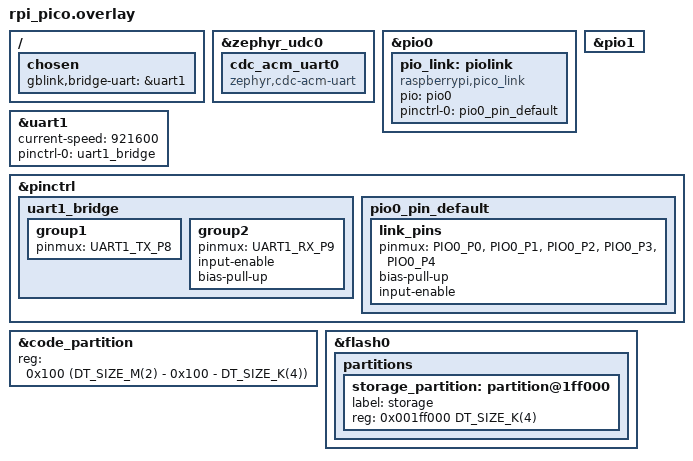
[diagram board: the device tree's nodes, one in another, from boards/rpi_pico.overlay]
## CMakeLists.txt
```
cmake_minimum_required(VERSION 3.20.0)

set(CMAKE_CXX_STANDARD 20)
set(CMAKE_CXX_STANDARD_REQUIRED ON)

# The following resolves the Zephyr location using the ZEPHYR_BASE environment variable.
# The `REQUIRED HINTS $ENV{ZEPHYR_BASE}` is optional in case you're not using `west zephyr-export`
# https://docs.zephyrproject.org/latest/develop/west/zephyr-cmds.html#installing-cmake-packages-west-zephyr-export

# Only set ZEPHYR_MODULES manually if modules are vendored locally.
# When building with west, modules are discovered automatically.
if(EXISTS "${CMAKE_SOURCE_DIR}/modules/hal/rpi_pico")
    set(ZEPHYR_MODULES "${CMAKE_SOURCE_DIR}/modules/hal/rpi_pico" "${CMAKE_SOURCE_DIR}/modules/hal/cmsis")
endif()

set(BOARD rpi_pico)

find_package(Zephyr REQUIRED HINTS "${CMAKE_SOURCE_DIR}/zephyr" $ENV{ZEPHYR_BASE})

project(
    EmptyApp
    VERSION 0.1
    DESCRIPTION "Empty Zephyr application."
    LANGUAGES C
)

# The target "app" is defined in Zephyr's CMake package and is the default target for Zephyr apps.
target_sources(
    app
    PRIVATE
    src/main.cpp
    src/hardware.cpp
    src/persist.cpp
)

set_compiler_property(PROPERTY diagnostic -fdiagnostics-color=never)


# The wireless adapter's transfer path runs from RAM: the GBA clocks the next
# word about 40us after the last, and executing ~4KB of protocol code in place
# shares the RP2040's 16KB XIP cache with the kernel, bridge UART and USB, where
# a cold pass costs more than that whole budget.
zephyr_code_relocate(FILES src/layers/link/rfuLinkLayer.c src/sections/rfuProtocolSection.cpp
                     LOCATION RAM_TEXT)

add_subdirectory(src/layers)
add_subdirectory(src/sections)
add_subdirectory(src/module)
```

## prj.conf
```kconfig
CONFIG_GPIO=y
CONFIG_DMA=y
CONFIG_COUNTER=y
CONFIG_EVENTS=y

CONFIG_SPEED_OPTIMIZATIONS=y
CONFIG_DEBUG=n

CONFIG_STDOUT_CONSOLE=y
CONFIG_USB_DEVICE_STACK=y
CONFIG_USB_DEVICE_BOS=y
CONFIG_USB_COMPOSITE_DEVICE=y
CONFIG_USB_CDC_ACM=y
# Composite (vendor + CDC) needs more concurrent transfers than the defaults.
CONFIG_USB_MAX_NUM_TRANSFERS=8
CONFIG_USB_NUMOF_EP_WRITE_RETRIES=10
CONFIG_SERIAL=y
CONFIG_USB_DEVICE_PRODUCT="GBLink USB"
CONFIG_USB_DEVICE_VID=0x1209
CONFIG_USB_DEVICE_PID=0xB011
CONFIG_UART_INTERRUPT_DRIVEN=y
CONFIG_UART_LINE_CTRL=y
CONFIG_RING_BUFFER=y
CONFIG_USB_DEVICE_INITIALIZE_AT_BOOT=n

CONFIG_CPP=y
CONFIG_STD_CPP20=y
CONFIG_NEWLIB_LIBC=y
CONFIG_NEWLIB_LIBC_NANO=y
CONFIG_REQUIRES_FULL_LIBCPP=y

CONFIG_TICKLESS_KERNEL=y

CONFIG_THREAD_MONITOR=y
CONFIG_THREAD_NAME=y
CONFIG_DEBUG_THREAD_INFO=y
CONFIG_ASSERT=y

CONFIG_PINCTRL=y

# Flash storage for persistent settings (the WebUSB landing-page toggle).
CONFIG_FLASH=y
CONFIG_FLASH_MAP=y
CONFIG_FLASH_PAGE_LAYOUT=y

CONFIG_SECTIONS_USE_MASTER_MODE=y
CONFIG_REBOOT=y
# Driving SD low is opt-in (off by default). For rare compatibility issues with some GBAs.
CONFIG_GB_LINK_DRIVE_SD_LOW=n

# Lets zephyr_code_relocate() place the wireless adapter's transfer path in RAM.
CONFIG_CODE_DATA_RELOCATION=y
```

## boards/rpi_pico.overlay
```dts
#include <zephyr/dt-bindings/pinctrl/rpi-pico-rp2040-pinctrl.h>

&zephyr_udc0 {
    cdc_acm_uart0: cdc_acm_uart0 {
        compatible = "zephyr,cdc-acm-uart";
    };
};

&pio0 {
    status = "okay";

    pio_link: piolink {
        compatible = "raspberrypi,pico_link";
        status = "okay";
        pio = <&pio0>;
        pinctrl-0 = <&pio0_pin_default>;
        pinctrl-names = "default";
    };
};

&pio1 {
    status = "okay";
};

/*
 * Bridge UART: the same 'GB' framed transport CDC-ACM carries, but wired
 * directly to a companion MCU instead of a host PC. GP8/GP9 is the only
 */
&uart1 {
    status = "okay";
    current-speed = <921600>;
    pinctrl-0 = <&uart1_bridge>;
    pinctrl-names = "default";
};

/ {
    chosen {
        gblink,bridge-uart = &uart1;
    };
};

&pinctrl {
    uart1_bridge: uart1_bridge {
        group1 {
            pinmux = <UART1_TX_P8>;
        };
        group2 {
            pinmux = <UART1_RX_P9>;
            input-enable;
            bias-pull-up;
        };
    };
    pio0_pin_default: pio0_pin_default {
        link_pins {
            pinmux = <PIO0_P0>, <PIO0_P1>, <PIO0_P2>, <PIO0_P3>, <PIO0_P4>;
            bias-pull-up;
            input-enable;
        };
    };
};

/*
 * Carve a 4 KB storage partition (one flash erase sector) off the top of flash
 * for persistent settings (URL toggle and LED customization). The application is
 * less than 200 KB and lives at the bottom, so the tail is free. The UF2 only writes
 * the app region, so this sector survives firmware updates.
 */
&code_partition {
    reg = <0x100 (DT_SIZE_M(2) - 0x100 - DT_SIZE_K(4))>;
};

&flash0 {
    partitions {
        storage_partition: partition@1ff000 {
            label = "storage";
            reg = <0x001ff000 DT_SIZE_K(4)>;
        };
    };
};
```

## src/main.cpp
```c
#include <zephyr/kernel.h>

#include "control.hpp"

#include "link_defines.h"

int main(void)
{
    Control g_control = Control();
    while (true)
    {
        g_control.executeMode();
    }

    return 0;
}
```

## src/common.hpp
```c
#include <algorithm>
#include <array>
#include <concepts>
#include <cstdint>
#include <span>
#include <stdint.h>

#pragma once

class TxValues
{
public:

    TxValues() = default;

    template<std::convertible_to<uint16_t>... Ts>
        requires (sizeof...(Ts) <= 3)
    TxValues(Ts... values)
        : m_count(sizeof...(Ts)), m_values{static_cast<uint16_t>(values)...}
    {}

    uint8_t size() { return m_count; }

    void push(uint16_t value) 
    { 
        m_values[m_count] = value;
        m_count++;    
    }

    const uint16_t& operator[](size_t index) {return m_values[index]; }

    std::span<const uint16_t> span() { return std::span(m_values).first(m_count); }

    auto begin() { return m_values.begin(); }

    auto end() { return m_values.begin() + m_count; }

    auto begin() const { return m_values.cbegin(); }

    auto end() const { return m_values.cbegin() + m_count; } 

private:

    uint8_t m_count = 0;
    std::array<uint16_t, 3> m_values = {};
};
```

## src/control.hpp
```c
#include "layers/transport.hpp"
#include "layers/packet/packetLayer.hpp"
#include "module/link.hpp"
#include "module/gb.hpp"
#include "module/advanceWars.hpp"
#include "module/eReader.hpp"
#include "module/battleChipGate.hpp"
#include "module/rfuWireless.hpp"
#include "sections/eReaderProtocolSection.hpp"
#include "sections/battleChipGateSection.hpp"
#include "sections/rfuProtocolSection.hpp"
#include "linkStatus.hpp"
#include "layers/packet/packetCommands/commands.hpp"
#include "module/moduleInterface.hpp"
#include "hardware.hpp"
#include "persist.hpp"
#include "firmware_version.hpp"

class Control
{
    enum class ControlCommand
    {
        SetMode = 0x00,
        Cancel = 0x01,
        EnterGBPrinter = 0x03,
        GetFirmwareInfo = 0x0F
    };

    enum class Mode
    {
        gbaLink = 0x01,
        gbLink = 0x02,
        gbPrinter = 0x03,
        advanceWars = 0x04,
        gbaEreader = 0x05,
        battleChipGate = 0x06,
        rfuWireless = 0x07,
    };

    static constexpr uint8_t callSetModeId = 0x01;

public:
    Control()
    {
        Transport::registerCommandHandler(receiveCommandHandler, this);

        k_sem_init(&m_waitForModeSemaphore, 0, 1);
    }

    void executeMode()
    {
        k_sem_take(&m_waitForModeSemaphore, K_FOREVER);
        // Capture the requested mode; callSetMode always sets m_mode before
        // giving the semaphore (including when preempting a running mode), so we
        // must not clobber it below. The variant travels with the mode.
        const Mode mode = m_mode;
        const uint8_t modeVariant = m_modeVariant;
        if (mode != m_previousMode) link_forgetSdPin();
        m_previousMode = mode;

        sendLinkStatus(LinkStatus::DeviceReady);

        switch (mode)
        {
            case Mode::gbaLink:
            {
                applyLedForSlot(LED_SLOT_GBA);

                Transport::registerDataHandler(usbLink_receiveHandler, nullptr);

                LinkModule linkModule;
                m_currentModule = &linkModule;
                linkModule.execute();

                sendLinkStatus(LinkStatus::LinkClosed);
                break;
            }

            case Mode::gbLink:
            {
                GBModule gbModule;
                m_currentModule = &gbModule;
                gbModule.execute();  // Sets blue LED internally

                sendLinkStatus(LinkStatus::GBSessionFinished);
                break;
            }

            case Mode::gbPrinter:
            {
                GBModule gbModule;
                m_currentModule = &gbModule;
                gbModule.executePrinterMode();  // Sets purple LED internally

                sendLinkStatus(LinkStatus::GBSessionFinished);
                break;
            }

            case Mode::advanceWars:
            {
                applyLedForSlot(LED_SLOT_ADVANCE_WARS);

                Transport::registerDataHandler(awProto_receiveHandler, nullptr);

                AdvanceWarsModule advanceWarsModule(
                    modeVariant == 2 ? awproto::GameVariant::aw2
                                     : awproto::GameVariant::aw1);
                m_currentModule = &advanceWarsModule;
                advanceWarsModule.execute();

                sendLinkStatus(LinkStatus::LinkClosed);
                break;
            }

            case Mode::gbaEreader:
            {
                applyLedForSlot(LED_SLOT_EREADER);

                Transport::registerDataHandler(erProto_receiveHandler, nullptr);

                const erproto::Profile profile =
                    modeVariant == 2 ? erproto::Profile::pokemonRuby :
                    modeVariant == 3 ? erproto::Profile::sma4JPN :
                    modeVariant == 4 ? erproto::Profile::pokemonRubyJPN :
                    modeVariant == 5 ? erproto::Profile::sma4EUR :
                    modeVariant == 6 ? erproto::Profile::sma4EURFra :
                    modeVariant == 7 ? erproto::Profile::sma4EURGer :
                    modeVariant == 8 ? erproto::Profile::sma4EUREsp :
                    modeVariant == 9 ? erproto::Profile::sma4EURIta :
                    modeVariant == 10 ? erproto::Profile::pokemonEmerald :
                    modeVariant == 11 ? erproto::Profile::pokemonEmeraldJPN :
                    modeVariant == 12 ? erproto::Profile::pokemonEmeraldFra :
                    modeVariant == 13 ? erproto::Profile::pokemonEmeraldGer
                                   : erproto::Profile::sma4;
                EReaderModule ereaderModule(profile);
                m_currentModule = &ereaderModule;
                ereaderModule.execute();

                sendLinkStatus(LinkStatus::LinkClosed);
                break;
            }

            case Mode::battleChipGate:
            {
                applyLedForSlot(LED_SLOT_BATTLE_CHIP_GATE);

                Transport::registerDataHandler(bcgProto_receiveHandler, nullptr);

                BattleChipGateModule battleChipGateModule(
                    bcgproto::gateTypeFromVariant(modeVariant));
                m_currentModule = &battleChipGateModule;
                battleChipGateModule.execute();

                sendLinkStatus(LinkStatus::LinkClosed);
                break;
            }

            // Wireless adapter (AGB-015) emulation, driven over the bridge UART
            // by a companion MCU rather than a host PC.
            case Mode::rfuWireless:
            {
                // No slot of its own: the stored palette holds seven entries and
                // an eighth would change the settings layout.
                applyLedForSlot(LED_SLOT_GBA);

                Transport::registerDataHandler(rfuProto_receiveHandler, nullptr);

                // Variant = role hint for the relay: 0 symmetric, 1 host, 2 client.
                RfuWirelessModule rfuModule(modeVariant);
                m_currentModule = &rfuModule;
                rfuModule.execute();

                sendLinkStatus(LinkStatus::LinkClosed);
                break;
            }
        }

        m_currentModule = nullptr;
        applyLedForSlot(LED_SLOT_IDLE); // green = connected, no active mode
    }

private:
    struct k_sem m_waitForModeSemaphore;
    Mode m_mode;
    uint8_t m_modeVariant = 0;
    std::optional<Mode> m_previousMode;

    IModule* m_currentModule = nullptr;

    bool canHandle(uint8_t command) { return (command & 0xF0) == 0x00; }

    // Hardware commands (0x40-0x4F) are device-level, handled regardless of active module
    bool isHardwareCommand(uint8_t command) { return (command & 0xF0) == 0x40; }

    enum class HardwareCommand : uint8_t
    {
        SetVoltage3V3 = 0x40,
        SetVoltage5V = 0x41,
        SetLEDColor = 0x42,
        RebootBootloader = 0x43,
        SetWebUsbLanding = 0x44,
        GetLedConfig = 0x45,
        SetModeLedColor = 0x46,
        ResetLedColors = 0x47,
        Reboot = 0x48,
        GetRfuIsrStats = 0x4c,
    };

    void receiveCommand(std::span<const uint8_t> data)
    {
        if (data.empty()) return;

        // Handle hardware commands first (device-level, always available)
        if (isHardwareCommand(data[0]))
        {
            return handleHardwareCommand(data);
        }

        if (m_currentModule != nullptr && m_currentModule->canHandle(data[0]))
        {
            return m_currentModule->receiveCommand(data);
        } 
        
        if (!canHandle(data[0])) return;
        switch (static_cast<ControlCommand>(data[0]))
        {
            // Optional third byte selects a game variant within the mode
            // (Advance Wars: 1 = AW1, 2 = AW2; e-reader: 1 = SMA4 US,
            // 2 = Pokemon RS US, 3 = SMA4 JPN, 4 = Pokemon RS JPN,
            // 5-9 = SMA4 EUR En/Fr/De/Es/It, 10 = Pokemon Emerald US,
            // 11 = Pokemon Emerald JPN, 12 = (Émeraude) / Emerald,
            // 13 = (Smaragd) / Emerald;
            // defaults to the first variant
            // for older clients that send only [command, mode]).
            case ControlCommand::SetMode:
                if (data.size() < 2) return;
                return callSetMode(static_cast<Mode>(data[1]),
                                   data.size() >= 3 ? data[2] : 0);
            case ControlCommand::Cancel: return callCancel();
            case ControlCommand::EnterGBPrinter: return callSetMode(Mode::gbPrinter);
            case ControlCommand::GetFirmwareInfo: return callGetFirmwareInfo();
            default: return;
        }
    }

    void handleHardwareCommand(std::span<const uint8_t> data)
    {
        switch (static_cast<HardwareCommand>(data[0]))
        {
            case HardwareCommand::SetVoltage3V3:
                Hardware::getInstance().setVoltage3V3();
                break;
            case HardwareCommand::SetVoltage5V:
                Hardware::getInstance().setVoltage5V();
                break;
            case HardwareCommand::SetLEDColor:
                if (data.size() >= 5) {
                    Hardware::getInstance().setLED(data[1], data[2], data[3], data[4] != 0);
                }
                break;
            case HardwareCommand::RebootBootloader:
                // Resets into the USB bootloader; does not return.
                Hardware::getInstance().rebootToBootloader();
                break;
            case HardwareCommand::SetWebUsbLanding:
                // Persist the WebUSB landing-page toggle; applies on next reconnect.
                if (data.size() >= 2) {
                    setLandingPageEnabled(data[1] != 0);
                }
                break;
            case HardwareCommand::GetLedConfig:
                return callGetLedConfig();
            case HardwareCommand::SetModeLedColor:
                // [0x46, slot, r, g, b] — persist a mode's LED colour.
                if (data.size() >= 5) {
                    setLedColor(data[1], data[2], data[3], data[4]);
                }
                break;
            case HardwareCommand::ResetLedColors:
                // Restore all per-mode LED colours to the built-in defaults.
                resetLedColors();
                break;
            case HardwareCommand::Reboot:
                // Warm-reboot into the app so persisted settings apply now; no return.
                Hardware::getInstance().reboot(); 
                break;
            case HardwareCommand::GetRfuIsrStats:
            {
                // Transfer-path timing: whether replies are staged inside the
                // GBA's inter-word gap.
                uint32_t v[5];
                rfuLink_isrStats(v);
                uint8_t resp[1 + sizeof(v)];
                resp[0] = 0x4c;
                for (unsigned i = 0; i < 5; i++)
                    for (unsigned b = 0; b < 4; b++)
                        resp[1 + i * 4 + b] = static_cast<uint8_t>(v[i] >> (8 * b));
                Transport::sendData(std::span<const uint8_t>(resp, sizeof(resp)));
                break;
            }
            default: break;
        }
    }

    void callGetLedConfig()
    {
        // [0x45, count, r0,g0,b0, ... r5,g5,b5]
        uint8_t info[2 + LED_SLOT_COUNT * 3];
        info[0] = static_cast<uint8_t>(HardwareCommand::GetLedConfig);
        info[1] = LED_SLOT_COUNT;
        for (uint8_t slot = 0; slot < LED_SLOT_COUNT; slot++) {
            getLedColor(slot, &info[2 + slot * 3]);
        }
        Transport::sendData(std::span<const uint8_t>(info, sizeof(info)));
    }

    //-////////////////////////////////////////////////////////////////////////////////////////////////////////-//
    // CALLS
    //-////////////////////////////////////////////////////////////////////////////////////////////////////////-//

    void callSetMode(Mode mode, uint8_t variant = 0)
    {
        m_mode = mode;
        m_modeVariant = variant;
        // If a mode is already running, cancel it so executeMode unblocks and
        // switches to the new mode (otherwise SetMode would queue behind a mode
        // that never exits). Same cancel path the web "cancel" command uses.
        if (m_currentModule != nullptr)
        {
            m_currentModule->cancel();
        }
        k_sem_give(&m_waitForModeSemaphore);
    }

    void callCancel()
    {
        if (m_currentModule != nullptr) m_currentModule->cancel();
    }

    void callGetFirmwareInfo()
    {
        const uint8_t info[] = {
            0x0F, // Echo back the command ID so web app knows this is a firmware info response
            fw::versionMajor,
            fw::versionMinor,
            fw::versionPatch,
            // Byte 4: WebUSB landing-page enabled (1) / disabled (0). Older web
            // apps simply ignore the extra byte.
            static_cast<uint8_t>(landingPageEnabled() ? 1 : 0)
        };
        Transport::sendData(std::span<const uint8_t>(info, sizeof(info)));
    }

    //-////////////////////////////////////////////////////////////////////////////////////////////////////////-//

    static void receiveCommandHandler(std::span<const uint8_t> receivedData, void* userData)
    {
        Control* self = static_cast<Control*>(userData);
        self->receiveCommand(receivedData);
    }
};
```

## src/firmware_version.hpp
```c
#pragma once

#include <cstdint>

// Single source for the firmware version. It is reported over the
// protocol (GetFirmwareInfo) and folded into the USB bcdDevice (see usbLayer.cpp).
//
// Why bcdDevice tracks the version: Windows caches a device's MS OS / WinUSB
// driver binding keyed by VID/PID/bcdDevice. If bcdDevice never changes, a host
// that cached an older descriptor keeps the stale binding after a firmware
// update and will not re-read the corrected descriptors. Advancing bcdDevice on
// every release makes Windows treat it as a new device and re-enumerate cleanly.
namespace fw
{
    inline constexpr uint8_t versionMajor = 3;
    inline constexpr uint8_t versionMinor = 0;
    inline constexpr uint8_t versionPatch = 0;

    // Packed BCD nibbles 0x0<major><minor><patch>, e.g. 2.2.1 -> 0x0221.
    // Keep each field <= 9 to stay valid BCD.
    inline constexpr uint16_t bcdDevice =
        (static_cast<uint16_t>(versionMajor) << 8) |
        (static_cast<uint16_t>(versionMinor) << 4) |
        static_cast<uint16_t>(versionPatch);
}
```

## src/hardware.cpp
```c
#include "hardware.hpp"

#include <zephyr/kernel.h>
#include <zephyr/sys/reboot.h>
#include "hardware/pio.h"
#include "hardware/gpio.h"
#include "hardware/clocks.h"
#include "hardware/timer.h"

extern "C" {
#include <zephyr/drivers/misc/pio_rpi_pico/pio_rpi_pico.h>
}

// --- Pin Definitions ---
#define WS2812_PIN      16
#define VSWITCH_3V3_PIN 11
#define VSWITCH_5V_PIN  12

// --- WS2812 PIO Program (4 instructions) ---
static const uint16_t ws2812_program_instructions[] = {
    0x6221, //  0: out    x, 1       side 0 [2]
    0x1123, //  1: jmp    !x, 3      side 1 [1]
    0x1400, //  2: jmp    0          side 1 [4]
    0xa442, //  3: nop               side 0 [4]
};

static const struct pio_program ws2812_program = {
    .instructions = ws2812_program_instructions,
    .length = 4,
    .origin = -1,
};

// WS2812 uses pio1 (independent from link SPI on pio0)
static PIO g_ws2812_pio = NULL;
static uint g_ws2812_sm = 0;
static bool g_ws2812_initialized = false;

// --- Hardware Singleton ---

Hardware& Hardware::getInstance()
{
    static Hardware instance;
    return instance;
}

Hardware::Hardware()
{
    // Initialize voltage switching GPIOs (raw Pico SDK, matching linkLayer_pio.c pattern)
    gpio_init(VSWITCH_3V3_PIN);
    gpio_init(VSWITCH_5V_PIN);
    gpio_set_dir(VSWITCH_3V3_PIN, GPIO_OUT);
    gpio_set_dir(VSWITCH_5V_PIN, GPIO_OUT);

    // Safe state: both HIGH first
    gpio_put(VSWITCH_3V3_PIN, 1);
    gpio_put(VSWITCH_5V_PIN, 1);
    busy_wait_us(100);

    // Default to 3.3V mode
    gpio_put(VSWITCH_3V3_PIN, 0);

    // Initialize WS2812 NeoPixel
    ws2812Init();

    // Set initial LED to red (disconnected state)
    ws2812Set(0x000500); // GRB format: G=0x00, R=0x05, B=0x00
}

void Hardware::ws2812Init()
{
    // Pico SDK defines 'pio1' as a macro (pio1_hw) which breaks DT_NODELABEL.
    // Temporarily undefine it so device tree lookup works.
    #undef pio1
    const struct device* dev = DEVICE_DT_GET(DT_NODELABEL(pio1));
    if (!device_is_ready(dev)) {
        return;
    }

    g_ws2812_pio = pio_rpi_pico_get_pio(dev);
    pio_rpi_pico_allocate_sm(dev, &g_ws2812_sm);

    uint offset = pio_add_program(g_ws2812_pio, &ws2812_program);

    // Configure state machine for WS2812 protocol
    pio_gpio_init(g_ws2812_pio, WS2812_PIN);
    pio_sm_set_consecutive_pindirs(g_ws2812_pio, g_ws2812_sm, WS2812_PIN, 1, true);

    pio_sm_config c = pio_get_default_sm_config();
    sm_config_set_sideset(&c, 1, false, false);
    sm_config_set_sideset_pins(&c, WS2812_PIN);
    sm_config_set_out_shift(&c, false, true, 24);
    sm_config_set_fifo_join(&c, PIO_FIFO_JOIN_TX);
    sm_config_set_wrap(&c, offset, offset + 3);
    sm_config_set_clkdiv(&c, clock_get_hz(clk_sys) / (800000.0f * 8.0f));

    pio_sm_init(g_ws2812_pio, g_ws2812_sm, offset, &c);
    pio_sm_set_enabled(g_ws2812_pio, g_ws2812_sm, true);

    g_ws2812_initialized = true;
}

void Hardware::ws2812Set(uint32_t grb)
{
    if (!g_ws2812_initialized) return;
    pio_sm_put_blocking(g_ws2812_pio, g_ws2812_sm, grb << 8u);
}

// --- Public API ---

void Hardware::setVoltage3V3()
{
    // Both HIGH first (safe off), then pull 3.3V LOW
    gpio_put(VSWITCH_3V3_PIN, 1);
    gpio_put(VSWITCH_5V_PIN, 1);
    busy_wait_us(100);
    gpio_put(VSWITCH_3V3_PIN, 0);
}

void Hardware::setVoltage5V()
{
    // Both HIGH first (safe off), then pull 5V LOW
    gpio_put(VSWITCH_3V3_PIN, 1);
    gpio_put(VSWITCH_5V_PIN, 1);
    busy_wait_us(100);
    gpio_put(VSWITCH_5V_PIN, 0);
}

void Hardware::setLED(uint8_t r, uint8_t g, uint8_t b, bool on)
{
    if (on) {
        // NeoPixel expects GRB format
        uint32_t grb = ((uint32_t)g << 16) | ((uint32_t)r << 8) | b;
        ws2812Set(grb);
    } else {
        ws2812Set(0x000000);
    }
}

// Reset into the RP2040 USB bootloader (BOOTSEL/PICOBOOT) so the host can
// reflash over WebUSB. The Zephyr hal_rpi_pico module does not ship
// pico/bootrom.h, so look up reset_usb_boot() in the bootrom directly:
// the func-table pointer lives at 0x14 and the table-lookup routine at 0x18.
void Hardware::rebootToBootloader()
{
    typedef void *(*rom_table_lookup_fn)(uint16_t *table, uint32_t code);
    typedef void (*reset_usb_boot_fn)(uint32_t gpio_mask, uint32_t disable_mask);

    uint16_t *func_table = (uint16_t *)(uintptr_t)(*(uint16_t *)0x14);
    rom_table_lookup_fn rom_table_lookup =
        (rom_table_lookup_fn)(uintptr_t)(*(uint16_t *)0x18);

    const uint32_t reset_usb_boot_code = (uint32_t)('U' | ('B' << 8));
    reset_usb_boot_fn reset_usb_boot =
        (reset_usb_boot_fn)rom_table_lookup(func_table, reset_usb_boot_code);

    reset_usb_boot(0, 0); // does not return
}

// Warm-reboot back into the application (not the bootloader). Used to "apply now"
// after settings changes — persisted LED colours are re-read at boot.
void Hardware::reboot()
{
    sys_reboot(SYS_REBOOT_COLD); // does not return
}

// --- Boot-time Initialization ---
static int hardware_init()
{
    Hardware::getInstance();
    return 0;
}

SYS_INIT(hardware_init, APPLICATION, 0);
```

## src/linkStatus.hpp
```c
#include <zephyr/kernel.h>
#include "./layers/transport.hpp"

#pragma once

enum class LinkStatus : uint16_t
{
    GameboyConnected = 0xFF00,
    GameboyDisconnected = 0xFF01,

    AwaitPlayerSettings = 0xFF02,

    HandshakeReceived = 0xFF03,
    HandshakeFinished = 0xFF04,

    LinkConnected = 0xFF05,
    LinkReconnecting = 0xFF06,
    LinkClosed = 0xFF07,

    DeviceReady = 0xFF08,

    GBModeActive = 0xFF0A,
    GBPrinterModeActive = 0xFF0B,
    GBSessionFinished = 0xFF0C,

    StatusDebug = 0xFFFF
};

inline bool sendLinkStatus(LinkStatus status)
{
    return Transport::sendStatus(std::span<const uint8_t, 2>(reinterpret_cast<const uint8_t*>(&status), 2));
}
```

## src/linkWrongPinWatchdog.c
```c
#include "layers/linkLayer.h"

#include <zephyr/kernel.h>

/* Wrong-pin watchdog for classic slave modes (trade emu, GBA link relay, AW
 * slave). Cable detection is a heuristic and can pick the wrong SD pin (GBA
 * already in link mode at detect time, or cable plugged in afterwards). The
 * partner clocking SC while zero words arrive is proof of the wrong pin — SC
 * is the same pin for both cable types — so after sustained evidence the
 * watchdog flips the SD path and reconfigures, once per armed session.
 * Requiring both SC levels (a real toggle) rejects a stuck line, and any
 * received word disarms the watchdog until the next configure. */
static void wrongPinWatchdogThread(void* a, void* b, void* c)
{
    (void)a; (void)b; (void)c;
    bool scSeenLow = false;
    bool scSeenHigh = false;
    int ticks = 0;
    int clockingIntervals = 0;

    for (;;)
    {
        if (link_getSlaveMode() != CLASSIC || link_getWrongPinFlipsLeft() == 0)
        {
            scSeenLow = scSeenHigh = false;
            ticks = 0;
            clockingIntervals = 0;
            k_sleep(K_MSEC(100));
            continue;
        }

        k_sleep(K_MSEC(1));
        if (link_readPartnerPins() & 0x01) scSeenLow = true;
        else scSeenHigh = true;

        if (++ticks < 550) continue;
        ticks = 0;

        const bool scToggled = scSeenLow && scSeenHigh;
        scSeenLow = scSeenHigh = false;

        if (link_getReceivedWordCount() != 0)
        {
            clockingIntervals = 0;
            continue;
        }
        if (scToggled) clockingIntervals++;

        if (clockingIntervals >= 4)
        {
            clockingIntervals = 0;
            link_tryWrongPinRecovery();
        }
    }
}

K_THREAD_DEFINE(wrongPinWatchdog_tid, 768, wrongPinWatchdogThread,
                NULL, NULL, NULL, 12, 0, 0);
```

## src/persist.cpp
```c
#include "persist.hpp"
#include "hardware.hpp"
#include <cstring>
#include <zephyr/storage/flash_map.h>

namespace
{
    #define STORAGE_PARTITION_ID FIXED_PARTITION_ID(storage_partition)

    constexpr uint8_t SETTINGS_MAGIC = 0x5A;
    constexpr uint8_t SETTINGS_VERSION = 8; // bumped for Battle Chip Gate deep-blue default

    struct PersistSettings
    {
        uint8_t magic;
        uint8_t version;
        uint8_t landing;                       // 0 = disabled, else enabled
        uint8_t led[LED_SLOT_COUNT][3];        // per-slot logical RGB
        // Up to 2.2.8 the next byte held the cable selection: a field added here needs a version bump.
    };

    // Real-colour defaults at a uniform 12.5% brightness (32/255) so every mode's
    // brightness slider starts at the same place. WS2812 magnitude = brightness.
    const uint8_t kDefaultColors[LED_SLOT_COUNT][3] = {
        { 0,   32,  0   }, // idle/connected — green
        { 32,  32,  0   }, // GBA/Celio — yellow
        { 0,   0,   32  }, // GB/GBC — blue
        { 32,  0,   32  }, // printer — purple
        { 32,  32,  32  }, // Advance Wars — white
        { 0,   10,  32  }, // e-reader — light blue
        { 2,   4,   32  }, // Battle Chip Gate — deep blue
    };

    void fillDefaults(PersistSettings& s)
    {
        s.magic = SETTINGS_MAGIC;
        s.version = SETTINGS_VERSION;
        s.landing = 1;
        memcpy(s.led, kDefaultColors, sizeof(s.led));
    }

    // Defaults when flash is unwritten; older layouts migrate in place (written
    // back on the next save).
    PersistSettings loadSettings()
    {
        PersistSettings s{};
        const struct flash_area *fa;
        if (flash_area_open(STORAGE_PARTITION_ID, &fa) != 0) {
            fillDefaults(s);
            return s;
        }
        flash_area_read(fa, 0, &s, sizeof(s));
        flash_area_close(fa);

        if (s.magic != SETTINGS_MAGIC) {
            fillDefaults(s);
        } else if (s.version == 6 || s.version == 7) {
            // No Battle Chip Gate slot yet (v7 kept its cable selection there).
            s.version = SETTINGS_VERSION;
            memcpy(s.led[LED_SLOT_BATTLE_CHIP_GATE],
                   kDefaultColors[LED_SLOT_BATTLE_CHIP_GATE], 3);
        } else if (s.version != SETTINGS_VERSION) {
            fillDefaults(s);
        }
        return s;
    }

    void saveSettings(const PersistSettings& s)
    {
        const struct flash_area *fa;
        if (flash_area_open(STORAGE_PARTITION_ID, &fa) != 0) {
            return;
        }
        // Flash must be erased before writing; RP2040 write-block-size is 1.
        flash_area_erase(fa, 0, fa->fa_size);
        flash_area_write(fa, 0, &s, sizeof(s));
        flash_area_close(fa);
    }
}

bool landingPageEnabled()
{
    return loadSettings().landing != 0;
}

void setLandingPageEnabled(bool enabled)
{
    PersistSettings s = loadSettings();
    s.landing = enabled ? 1 : 0;
    saveSettings(s);
}

void getLedColor(uint8_t slot, uint8_t out[3])
{
    if (slot >= LED_SLOT_COUNT) { out[0] = out[1] = out[2] = 0; return; }
    PersistSettings s = loadSettings();
    out[0] = s.led[slot][0];
    out[1] = s.led[slot][1];
    out[2] = s.led[slot][2];
}

void setLedColor(uint8_t slot, uint8_t r, uint8_t g, uint8_t b)
{
    if (slot >= LED_SLOT_COUNT) return;
    PersistSettings s = loadSettings();
    s.led[slot][0] = r;
    s.led[slot][1] = g;
    s.led[slot][2] = b;
    saveSettings(s);
}

void resetLedColors()
{
    PersistSettings s = loadSettings();
    memcpy(s.led, kDefaultColors, sizeof(s.led));
    saveSettings(s);
}

void applyLedForSlot(uint8_t slot)
{
    uint8_t c[3];
    getLedColor(slot, c);
    Hardware::getInstance().setLED(c[0], c[1], c[2], true);
}
```

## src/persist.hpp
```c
#pragma once

#include <cstdint>

// Persistent device settings, stored in the dedicated 4 KB flash "storage"
// partition (see boards/rpi_pico.overlay). One versioned struct holds the
// WebUSB landing-page flag and the per-mode LED colors.

// Per-mode LED colour slots (fixed order — shared with the launcher UI).
enum LedSlot : uint8_t {
    LED_SLOT_IDLE = 0,        // connected, no active mode (green)
    LED_SLOT_GBA = 1,         // GBA trade/link (yellow)
    LED_SLOT_GBC = 2,         // GB/GBC link (blue)
    LED_SLOT_PRINTER = 3,     // GB printer (purple)
    LED_SLOT_ADVANCE_WARS = 4,// Advance Wars (white)
    LED_SLOT_EREADER = 5,  // e-Reader (light blue)
    LED_SLOT_BATTLE_CHIP_GATE = 6, // Battle Chip Gate (deep blue)
    LED_SLOT_COUNT = 7,
};

// WebUSB landing-page advertising. Default (unwritten flash) is enabled.
bool landingPageEnabled();
void setLandingPageEnabled(bool enabled);


// Per-mode LED colours (logical RGB, 0-255; the WS2812 driver does GRB packing).
void getLedColor(uint8_t slot, uint8_t out[3]);
void setLedColor(uint8_t slot, uint8_t r, uint8_t g, uint8_t b);
void resetLedColors(); // restore all slots to the built-in defaults

// Apply a slot's stored colour to the LED now (used at mode entry).
void applyLedForSlot(uint8_t slot);
```
